# N32G41x register map
Vendor: Nsingtech Ltd.; File version: 1.0
CPU: CM4 r0p1, little endian, no MPU, no FPU, 4 interrupt priority bits
Registers are 32-bit, read-write, reset 0x0 unless marked. A register's access mark holds for its fields unless they carry their own. Offsets are from the block's base; [hi:lo] are bit positions; 'fields as' and 'values as' point back to an identical list.

## RTC — Real-Time Clock
Base 0x40002800
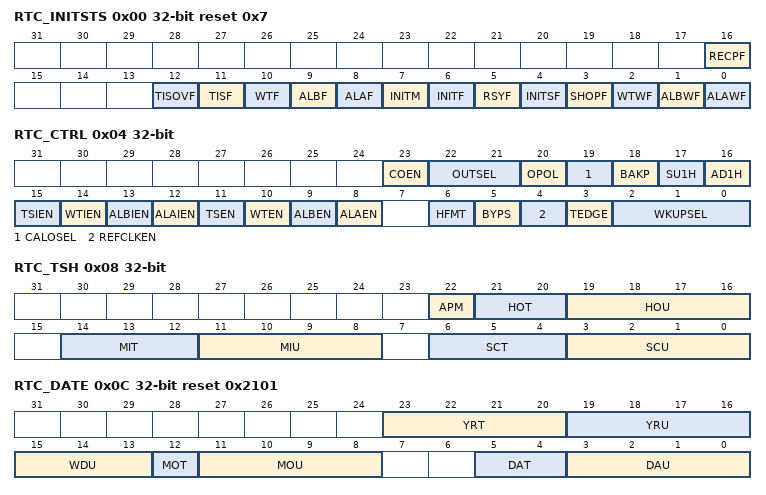
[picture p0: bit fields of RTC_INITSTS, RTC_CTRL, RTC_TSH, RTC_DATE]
0x00 RTC_INITSTS reset 0x7 — RTC Initial Status Register
  [16] RECPF ro — Recalibration pending flag
  [12] TISOVF — Timestamp overflow flag
  [11] TISF — Timestamp flag
  [10] WTF — Wakeup timer flag
  [9] ALBF — Alarm B flag
  [8] ALAF — Alarm A flag
  [7] INITM — Initialization mode
  [6] INITF ro — Initialization flag
  [5] RSYF — Registers synchronization flag
  [4] INITSF ro — Initial state flag
  [3] SHOPF ro — Shift operation pending flag
  [2] WTWF ro — Wakeup timer write flag
  [1] ALBWF ro — Alarm B write flag
  [0] ALAWF ro — Alarm A write flag
0x04 RTC_CTRL — RTC Control Register
  [23] COEN — Calibration output enable
  [22:21] OUTSEL — Output selection
  [20] OPOL — Output polarity
  [19] CALOSEL — Calibration output selection
  [18] BAKP — Daylight saving backup
  [17] SU1H wo — Subtract 1 hour
  [16] AD1H wo — Add 1 hour
  [15] TSIEN — Timestamp interrupt enable
  [14] WTIEN — Wakeup timer interrupt enable
  [13] ALBIEN — Alarm B interrupt enable
  [12] ALAIEN — Alarm A interrupt enable
  [11] TSEN — Timestamp enable
  [10] WTEN — Wakeup timer enable
  [9] ALBEN — Alarm B enable
  [8] ALAEN — Alarm A enable
  [6] HFMT — Hour format
  [5] BYPS — Bypass shadow registers
  [4] REFCLKEN — RTC_REFIN detection enable
  [3] TEDGE — Timestamp event trigger edge
  [2:0] WKUPSEL — Wakeup clock selection
0x08 RTC_TSH — RTC Calendar Time Register
  [22] APM — AM/PM format
  [21:20] HOT — Hour tens BCD
  [19:16] HOU — Hour units BCD
  [14:12] MIT — Minute tens BCD
  [11:8] MIU — Minute units BCD
  [6:4] SCT — Second tens BCD
  [3:0] SCU — Second units BCD
0x0C RTC_DATE reset 0x2101 — RTC Calendar Date Register
  [23:20] YRT — Year tens BCD
  [19:16] YRU — Year units BCD
  [15:13] WDU — Week day units
  [12] MOT — Month tens BCD
  [11:8] MOU — Month units BCD
  [5:4] DAT — Date tens BCD
  [3:0] DAU — Date units BCD
0x10 RTC_WRP wo — RTC Write Protection Register
  [7:0] PKEY — Write protection key
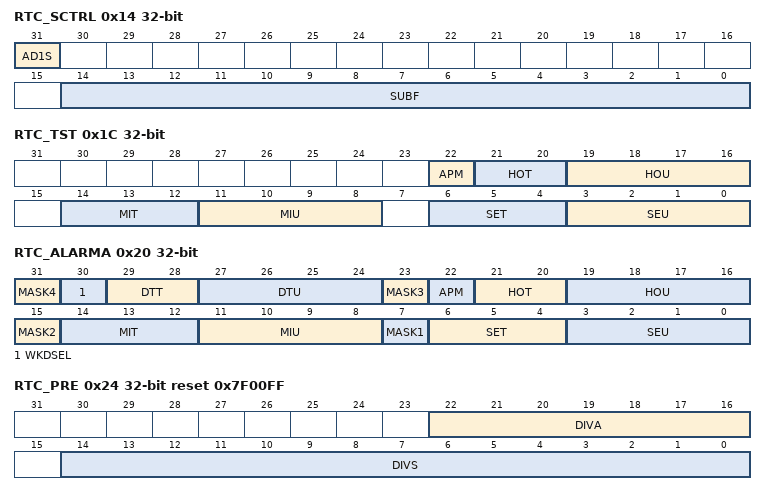
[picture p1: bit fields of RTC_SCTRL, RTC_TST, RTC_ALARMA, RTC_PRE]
0x14 RTC_SCTRL wo — RTC Shift Control Register
  [31] AD1S — Add one second
  [14:0] SUBF — Subtract sub-second value
0x18 RTC_SUBS ro — RTC Sub-Second Register
  [15:0] SS — Sub-second value
0x1C RTC_TST ro — RTC Timestamp Time Register
  [22] APM — AM/PM format
  [21:20] HOT — Hour tens BCD
  [19:16] HOU — Hour units BCD
  [14:12] MIT — Minute tens BCD
  [11:8] MIU — Minute units BCD
  [6:4] SET — Second tens BCD
  [3:0] SEU — Second units BCD
0x20 RTC_ALARMA
  [31] MASK4 — Alarm date mask
  [30] WKDSEL — Week day selection
  [29:28] DTT — Date tens BCD
  [27:24] DTU — Date units BCD
  [23] MASK3 — Alarm hours mask
  [22] APM — AM/PM format
  [21:20] HOT — Hour tens BCD
  [19:16] HOU — Hour units BCD
  [15] MASK2 — Alarm minutes mask
  [14:12] MIT — Minute tens BCD
  [11:8] MIU — Minute units BCD
  [7] MASK1 — Alarm seconds mask
  [6:4] SET — Second tens BCD
  [3:0] SEU — Second units BCD
0x24 RTC_PRE reset 0x7F00FF — RTC Prescaler Register
  [22:16] DIVA — Asynchronous prescaler
  [14:0] DIVS — Synchronous prescaler
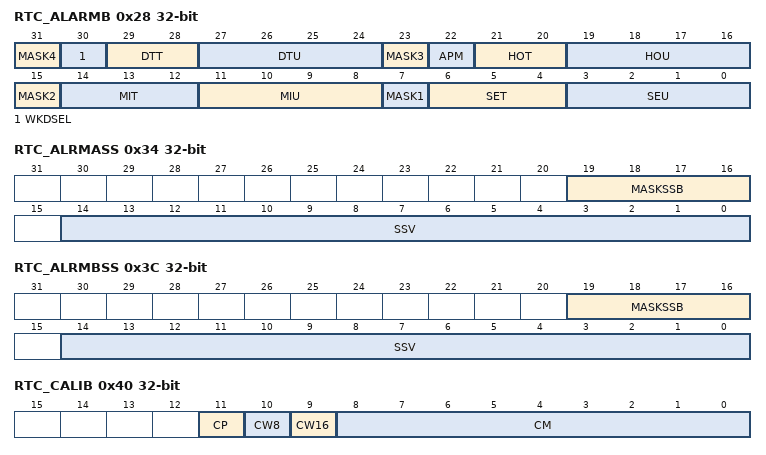
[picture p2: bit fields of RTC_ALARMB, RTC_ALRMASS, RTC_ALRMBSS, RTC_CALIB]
0x28 RTC_ALARMB
  fields as RTC_ALARMA
0x2C RTC_WKUPT reset 0xFFFF — RTC Wakeup Timer Register
  [15:0] WKUPT — Wakeup auto-reload value
0x34 RTC_ALRMASS — RTC Alarm A Sub-Second Register
  [19:16] MASKSSB — Mask most-significant bits
  [14:0] SSV — Sub-second value
0x38 RTC_OPT — RTC Options Register
  [0] TYPE — Output type
0x3C RTC_ALRMBSS — RTC Alarm B Sub-Second Register
  fields as RTC_ALRMASS
0x40 RTC_CALIB — RTC Calibration Register
  [11] CP — Increase frequency 488.5ppm
  [10] CW8 — Use 8-second calibration
  [9] CW16 — Use 16-second calibration
  [8:0] CM — Negative calibration
0x44 RTC_TSSS ro — RTC Timestamp Sub-Second Register
  [15:0] SSE — Sub-second value
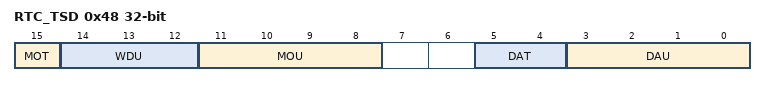
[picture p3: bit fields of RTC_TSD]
0x48 RTC_TSD ro — RTC Timestamp Date Register
  [15] MOT — Month tens BCD
  [14:12] WDU — Week day units
  [11:8] MOU — Month units BCD
  [5:4] DAT — Date tens BCD
  [3:0] DAU — Date units BCD
